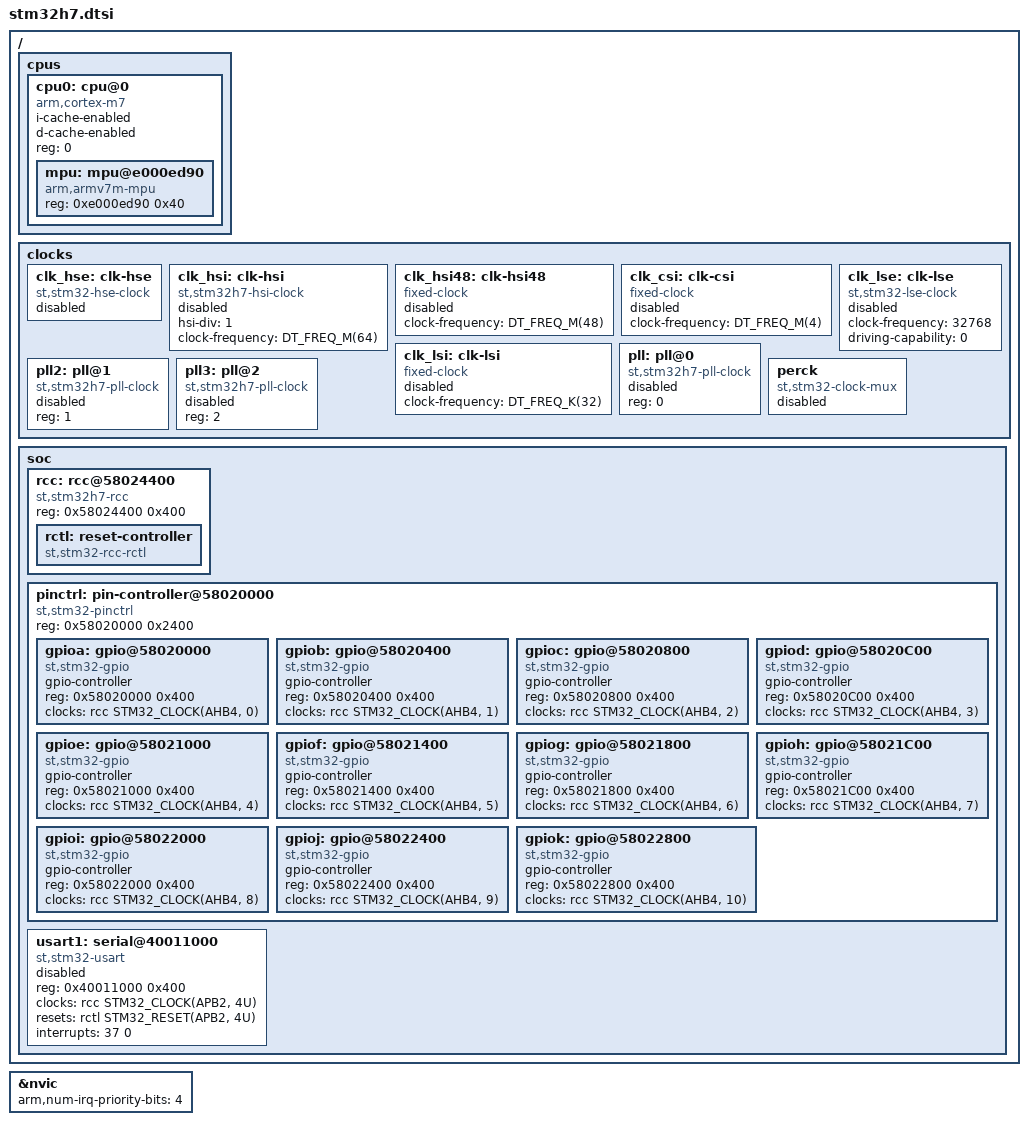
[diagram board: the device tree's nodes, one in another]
/*
 * Copyright (c) 2019 Linaro Limited
 * Copyright (c) 2019 Centaur Analytics, Inc
 * Copyright (c) 2020 Teslabs Engineering S.L.
 * Copyright (c) 2024 STMicroelectronics
 *
 * SPDX-License-Identifier: Apache-2.0
 */

#include <arm/armv7-m.dtsi>
#include <dt-bindings/clock/stm32h7_clock.h>
#include <dt-bindings/gpio/gpio.h>
#include <dt-bindings/i2c/i2c.h>
#include <dt-bindings/pwm/pwm.h>
#include <dt-bindings/pwm/stm32_pwm.h>
#include <dt-bindings/dma/stm32_dma.h>
#include <dt-bindings/adc/stm32h7_adc.h>
#include <dt-bindings/reset/stm32h7_reset.h>
#include <dt-bindings/adc/adc.h>
#include <dt-bindings/memory-controller/stm32-fmc-sdram.h>
#include <dt-bindings/memory-attr/memory-attr.h>
#include <dt-bindings/memory-attr/memory-attr-arm.h>
#include <freq.h>

/ {
	cpus {
		#address-cells = <1>;
		#size-cells = <0>;

		cpu0: cpu@0 {
			device_type = "cpu";
			compatible = "arm,cortex-m7";
			i-cache-enabled;
			d-cache-enabled;
			reg = <0>;
			#address-cells = <1>;
			#size-cells = <1>;

			mpu: mpu@e000ed90 {
				compatible = "arm,armv7m-mpu";
				reg = <0xe000ed90 0x40>;
			};
		};
	};

	clocks {
		#address-cells = <1>;
		#size-cells = <0>;

		clk_hse: clk-hse {
			#clock-cells = <0>;
			compatible = "st,stm32-hse-clock";
			status = "disabled";
		};

		clk_hsi: clk-hsi {
			#clock-cells = <0>;
			compatible = "st,stm32h7-hsi-clock";
			hsi-div = <1>;	/* HSI RC: 64MHz, hsi_clk = 64MHz */
			clock-frequency = <DT_FREQ_M(64)>;
			status = "disabled";
		};

		clk_hsi48: clk-hsi48 {
			#clock-cells = <0>;
			compatible = "fixed-clock";
			clock-frequency = <DT_FREQ_M(48)>;
			status = "disabled";
		};

		clk_csi: clk-csi {
			#clock-cells = <0>;
			compatible = "fixed-clock";
			clock-frequency = <DT_FREQ_M(4)>;
			status = "disabled";
		};

		clk_lse: clk-lse {
			#clock-cells = <0>;
			compatible = "st,stm32-lse-clock";
			clock-frequency = <32768>;
			driving-capability = <0>;
			status = "disabled";
		};

		clk_lsi: clk-lsi {
			#clock-cells = <0>;
			compatible = "fixed-clock";
			clock-frequency = <DT_FREQ_K(32)>;
			status = "disabled";
		};

		pll: pll@0 {
			#clock-cells = <0>;
			compatible = "st,stm32h7-pll-clock";
			reg = <0>;
			status = "disabled";
		};

		pll2: pll@1 {
			#clock-cells = <0>;
			compatible = "st,stm32h7-pll-clock";
			reg = <1>;
			status = "disabled";
		};

		pll3: pll@2 {
			#clock-cells = <0>;
			compatible = "st,stm32h7-pll-clock";
			reg = <2>;
			status = "disabled";
		};

		perck: perck {
			#clock-cells = <0>;
			compatible = "st,stm32-clock-mux";
			status = "disabled";
		};
	};

	soc {
		rcc: rcc@58024400 {
			compatible = "st,stm32h7-rcc";
			#clock-cells = <2>;
			reg = <0x58024400 0x400>;

			rctl: reset-controller {
				compatible = "st,stm32-rcc-rctl";
				#reset-cells = <1>;
			};
		};
		pinctrl: pin-controller@58020000 {
			compatible = "st,stm32-pinctrl";
			#address-cells = <1>;
			#size-cells = <1>;
			reg = <0x58020000 0x2400>;

			gpioa: gpio@58020000 {
				compatible = "st,stm32-gpio";
				gpio-controller;
				#gpio-cells = <2>;
				reg = <0x58020000 0x400>;
				clocks = <&rcc STM32_CLOCK(AHB4, 0)>;
			};
			gpiob: gpio@58020400 {
				compatible = "st,stm32-gpio";
				gpio-controller;
				#gpio-cells = <2>;
				reg = <0x58020400 0x400>;
				clocks = <&rcc STM32_CLOCK(AHB4, 1)>;
			};
			gpioc: gpio@58020800 {
				compatible = "st,stm32-gpio";
				gpio-controller;
				#gpio-cells = <2>;
				reg = <0x58020800 0x400>;
				clocks = <&rcc STM32_CLOCK(AHB4, 2)>;
			};
			gpiod: gpio@58020C00 {
				compatible = "st,stm32-gpio";
				gpio-controller;
				#gpio-cells = <2>;
				reg = <0x58020C00 0x400>;
				clocks = <&rcc STM32_CLOCK(AHB4, 3)>;
			};
			gpioe: gpio@58021000 {
				compatible = "st,stm32-gpio";
				gpio-controller;
				#gpio-cells = <2>;
				reg = <0x58021000 0x400>;
				clocks = <&rcc STM32_CLOCK(AHB4, 4)>;
			};
			gpiof: gpio@58021400 {
				compatible = "st,stm32-gpio";
				gpio-controller;
				#gpio-cells = <2>;
				reg = <0x58021400 0x400>;
				clocks = <&rcc STM32_CLOCK(AHB4, 5)>;
			};
			gpiog: gpio@58021800 {
				compatible = "st,stm32-gpio";
				gpio-controller;
				#gpio-cells = <2>;
				reg = <0x58021800 0x400>;
				clocks = <&rcc STM32_CLOCK(AHB4, 6)>;
			};
			gpioh: gpio@58021C00 {
				compatible = "st,stm32-gpio";
				gpio-controller;
				#gpio-cells = <2>;
				reg = <0x58021C00 0x400>;
				clocks = <&rcc STM32_CLOCK(AHB4, 7)>;
			};
			gpioi: gpio@58022000 {
				compatible = "st,stm32-gpio";
				gpio-controller;
				#gpio-cells = <2>;
				reg = <0x58022000 0x400>;
				clocks = <&rcc STM32_CLOCK(AHB4, 8)>;
			};
			gpioj: gpio@58022400 {
				compatible = "st,stm32-gpio";
				gpio-controller;
				#gpio-cells = <2>;
				reg = <0x58022400 0x400>;
				clocks = <&rcc STM32_CLOCK(AHB4, 9)>;
			};
			gpiok: gpio@58022800 {
				compatible = "st,stm32-gpio";
				gpio-controller;
				#gpio-cells = <2>;
				reg = <0x58022800 0x400>;
				clocks = <&rcc STM32_CLOCK(AHB4, 10)>;
			};
		};

		usart1: serial@40011000 {
			compatible = "st,stm32-usart", "st,stm32-uart";
			reg = <0x40011000 0x400>;
			clocks = <&rcc STM32_CLOCK(APB2, 4U)>;
			resets = <&rctl STM32_RESET(APB2, 4U)>;
			interrupts = <37 0>;
			status = "disabled";
		};
	};
};

&nvic {
	arm,num-irq-priority-bits = <4>;
};
